VERSION ""

NS_ :

BS_:

BU_: TestBoard DummyBoard

BO_ 17 TestMsg01: 0 TestBoard

BO_ 18 TestMsg02: 1 TestBoard
 SG_ Test1 : 0|8@1+ (1,0) [0|0] "" TestBoard

BO_ 19 TestMsg03: 2 TestBoard
 SG_ Test1 : 0|8@1+ (1,0) [0|0] "" TestBoard
 SG_ Test2 : 8|8@1+ (1,0) [0|0] "" TestBoard

BO_ 20 TestMsg04: 2 TestBoard
 SG_ Test1 : 0|16@1+ (1,0) [0|0] "" TestBoard

BO_ 21 TestMsg05: 2 TestBoard

BO_ 22 TestMsg06: 7 TestBoard
 SG_ Test1 : 32|16@1+ (1,0) [0|0] "" TestBoard

BO_ 23 TestMsg07: 8 TestBoard
 SG_ Test1 : 24|16@1+ (1,0) [0|0] "" TestBoard
 SG_ Test2 : 40|8@1+ (1,0) [0|0] "" TestBoard

BO_ 24 TestMsg08: 8 TestBoard
 SG_ Test2 : 40|8@1+ (1,0) [0|0] "" TestBoard
 SG_ Test1 : 24|16@1+ (1,0) [0|0] "" TestBoard

BO_ 2147483714 TestMsg09 : 1 TestBoard
 SG_ Test1 : 0|8@1+ (1,0) [0|0] "" TestBoard

BO_ 2147483715 TestMsg10 : 1 TestBoard
 SG_ Test1 : 0|8@1+ (1,0) [0|0] "" TestBoard

BO_ 2147483716 TestMsg11 : 1 TestBoard
 SG_ Test1 : 0|8@1+ (1,0) [0|0] "" TestBoard

BO_ 57 TestMsg12 : 1 TestBoard
 SG_ Test1 : 0|8@1+ (1,0) [0|0] "" TestBoard

BO_ 2147483648 TestMsg13 : 1 TestBoard
 SG_ Test1 : 0|8@1+ (1,0) [0|0] "" TestBoard

BO_ 2684354559 TestMsg14 : 1 TestBoard
 SG_ Test1 : 0|8@1+ (1,0) [0|0] "" TestBoard

BO_ 85 TestMsg15: 2 TestBoard
 SG_ Test1 : 7|16@0+ (1,0) [0|0] "" TestBoard

BO_ 86 TestMsg16: 7 TestBoard
 SG_ Test1 : 39|16@0- (1,0) [0|0] "" TestBoard

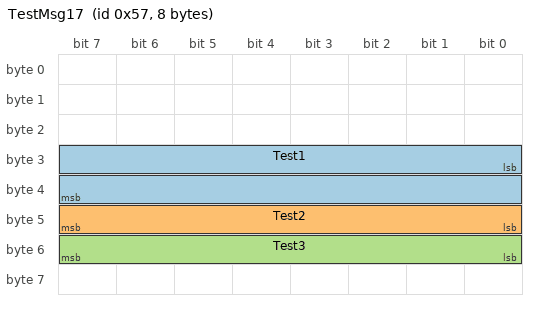
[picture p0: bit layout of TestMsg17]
BO_ 87 TestMsg17: 8 TestBoard
 SG_ Test1 : 24|16@1- (1,0) [0|0] "" TestBoard
 SG_ Test2 : 40|8@1- (1,0) [0|0] "" TestBoard
 SG_ Test3 : 55|8@0- (1,0) [0|0] "" TestBoard
